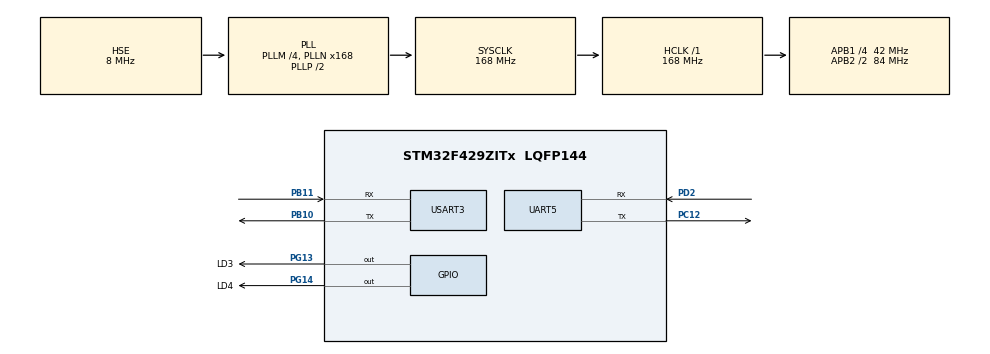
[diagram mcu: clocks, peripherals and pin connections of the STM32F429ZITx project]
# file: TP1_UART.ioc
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Mcu.Family=STM32F4
Mcu.Name=STM32F429ZITx
Mcu.Package=LQFP144
NVIC.PriorityGroup=NVIC_PRIORITYGROUP_4
NVIC.UART5_IRQn=true\:0\:0\:false\:false\:true\:true\:true
NVIC.USART3_IRQn=true\:0\:0\:false\:false\:true\:true\:true
PB10.Mode=Asynchronous
PB10.Signal=USART3_TX
PB11.Mode=Asynchronous
PB11.Signal=USART3_RX
PC12.Mode=Asynchronous
PC12.Signal=UART5_TX
PD2.Mode=Asynchronous
PD2.Signal=UART5_RX
PG13.GPIO_Label=LD3
PG13.Signal=GPIO_Output
PG14.GPIO_Label=LD4
PG14.Signal=GPIO_Output
PH0/OSC_IN.Mode=HSE-External-Oscillator
PH0/OSC_IN.Signal=RCC_OSC_IN
PH1/OSC_OUT.Mode=HSE-External-Oscillator
PH1/OSC_OUT.Signal=RCC_OSC_OUT
ProjectManager.HeapSize=0x200
ProjectManager.StackSize=0x400
ProjectManager.TargetToolchain=STM32CubeIDE
RCC.48MHZClocksFreq_Value=112000000
RCC.AHBFreq_Value=168000000
RCC.APB1CLKDivider=RCC_HCLK_DIV4
RCC.APB1Freq_Value=42000000
RCC.APB1TimFreq_Value=84000000
RCC.APB2CLKDivider=RCC_HCLK_DIV2
RCC.APB2Freq_Value=84000000
RCC.APB2TimFreq_Value=168000000
RCC.CortexFreq_Value=168000000
RCC.HCLKFreq_Value=168000000
RCC.HSE_VALUE=8000000
RCC.HSI_VALUE=16000000
RCC.LSE_VALUE=32768
RCC.PLLM=4
RCC.PLLN=168
RCC.PLLQ=3
RCC.PLLSAIN=50
RCC.PLLSourceVirtual=RCC_PLLSOURCE_HSE
RCC.SYSCLKFreq_VALUE=168000000
RCC.SYSCLKSource=RCC_SYSCLKSOURCE_PLLCLK
RCC.VCOOutputFreq_Value=336000000
UART5.VirtualMode=Asynchronous
UART5.WordLength=WORDLENGTH_8B
USART3.VirtualMode=VM_ASYNC
USART3.WordLength=WORDLENGTH_8B
board=STM32F429I-DISC1

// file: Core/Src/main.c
/* USER CODE BEGIN Header */
/**
  ******************************************************************************
  * @file           : main.c
  * @brief          : Main program body
  ******************************************************************************
  * @attention
  *
  * <h2><center>&copy; Copyright (c) 2020 STMicroelectronics.
  * All rights reserved.</center></h2>
  *
  * This software component is licensed by ST under Ultimate Liberty license
  * SLA0044, the "License"; You may not use this file except in compliance with
  * the License. You may obtain a copy of the License at:
  *                             www.st.com/SLA0044
  *
  ******************************************************************************
  */
/* USER CODE END Header */
#include "main.h"

UART_HandleTypeDef huart5;
UART_HandleTypeDef huart3;
uint8_t TableRxUART3[SIZE] = {0x31, 0x32, 0x33, 0x34, 0x35};
uint8_t TableRxUART5[SIZE] = {0x51, 0x52, 0x53, 0x54, 0x55};

void SystemClock_Config(void);
static void MX_GPIO_Init(void);
static void MX_UART5_Init(void);
static void MX_USART3_UART_Init(void);

int main(void)
{

  /* MCU Configuration--------------------------------------------------------*/

  /* Reset of all peripherals, Initializes the Flash interface and the Systick. */
  HAL_Init();

  /* Configure the system clock */
  SystemClock_Config();

  /* Initialize all configured peripherals */
  MX_GPIO_Init();
  MX_UART5_Init();
  MX_USART3_UART_Init();

  /* USER CODE BEGIN 2 */

  __HAL_UART_ENABLE_IT(&huart3, UART_IT_RXNE);
  __HAL_UART_ENABLE_IT(&huart5, UART_IT_RXNE);

  /* USER CODE END 2 */

  /* Infinite loop */
  while (1)
  {
	// Initialisation des tableaux de reception
	for(int i=0; i<SIZE; i++)
	{
		TableTxUART3[i]='\0';
		TableTxUART5[i]='\0';
	}
	HAL_GPIO_WritePin(LD3_GPIO_Port, LD3_Pin, 1);
	HAL_UART_Transmit(&huart3, TableRxUART3, SIZE, 100);
	HAL_UART_Transmit(&huart5, TableRxUART5, SIZE, 100);
	HAL_GPIO_WritePin(LD3_GPIO_Port, LD3_Pin, 0);
  }
}

void SystemClock_Config(void)
{
  RCC_OscInitTypeDef RCC_OscInitStruct = {0};
  RCC_ClkInitTypeDef RCC_ClkInitStruct = {0};

  /** Configure the main internal regulator output voltage
  */
  __HAL_RCC_PWR_CLK_ENABLE();
  __HAL_PWR_VOLTAGESCALING_CONFIG(PWR_REGULATOR_VOLTAGE_SCALE1);
  /** Initializes the RCC Oscillators according to the specified parameters
  * in the RCC_OscInitTypeDef structure.
  */
  RCC_OscInitStruct.OscillatorType = RCC_OSCILLATORTYPE_HSE;
  RCC_OscInitStruct.HSEState = RCC_HSE_ON;
  RCC_OscInitStruct.PLL.PLLState = RCC_PLL_ON;
  RCC_OscInitStruct.PLL.PLLSource = RCC_PLLSOURCE_HSE;
  RCC_OscInitStruct.PLL.PLLM = 4;
  RCC_OscInitStruct.PLL.PLLN = 168;
  RCC_OscInitStruct.PLL.PLLP = RCC_PLLP_DIV2;
  RCC_OscInitStruct.PLL.PLLQ = 3;
  if (HAL_RCC_OscConfig(&RCC_OscInitStruct) != HAL_OK)
  {
    Error_Handler();
  }
  /** Initializes the CPU, AHB and APB buses clocks
  */
  RCC_ClkInitStruct.ClockType = RCC_CLOCKTYPE_HCLK|RCC_CLOCKTYPE_SYSCLK
                              |RCC_CLOCKTYPE_PCLK1|RCC_CLOCKTYPE_PCLK2;
  RCC_ClkInitStruct.SYSCLKSource = RCC_SYSCLKSOURCE_PLLCLK;
  RCC_ClkInitStruct.AHBCLKDivider = RCC_SYSCLK_DIV1;
  RCC_ClkInitStruct.APB1CLKDivider = RCC_HCLK_DIV4;
  RCC_ClkInitStruct.APB2CLKDivider = RCC_HCLK_DIV2;

  if (HAL_RCC_ClockConfig(&RCC_ClkInitStruct, FLASH_LATENCY_5) != HAL_OK)
  {
    Error_Handler();
  }
}

static void MX_UART5_Init(void)
{

  huart5.Instance = UART5;
  huart5.Init.BaudRate = 115200;
  huart5.Init.WordLength = UART_WORDLENGTH_8B;
  huart5.Init.StopBits = UART_STOPBITS_1;
  huart5.Init.Parity = UART_PARITY_NONE;
  huart5.Init.Mode = UART_MODE_TX_RX;
  huart5.Init.HwFlowCtl = UART_HWCONTROL_NONE;
  huart5.Init.OverSampling = UART_OVERSAMPLING_16;
  if (HAL_UART_Init(&huart5) != HAL_OK)
  {
    Error_Handler();
  }

}

static void MX_USART3_UART_Init(void)
{

  huart3.Instance = USART3;
  huart3.Init.BaudRate = 115200;
  huart3.Init.WordLength = UART_WORDLENGTH_8B;
  huart3.Init.StopBits = UART_STOPBITS_1;
  huart3.Init.Parity = UART_PARITY_NONE;
  huart3.Init.Mode = UART_MODE_TX_RX;
  huart3.Init.HwFlowCtl = UART_HWCONTROL_NONE;
  huart3.Init.OverSampling = UART_OVERSAMPLING_16;
  if (HAL_UART_Init(&huart3) != HAL_OK)
  {
    Error_Handler();
  }

}

static void MX_GPIO_Init(void)
{
  GPIO_InitTypeDef GPIO_InitStruct = {0};

  /* GPIO Ports Clock Enable */
  __HAL_RCC_GPIOH_CLK_ENABLE();
  __HAL_RCC_GPIOB_CLK_ENABLE();
  __HAL_RCC_GPIOC_CLK_ENABLE();
  __HAL_RCC_GPIOD_CLK_ENABLE();
  __HAL_RCC_GPIOG_CLK_ENABLE();

  /*Configure GPIO pin Output Level */
  HAL_GPIO_WritePin(GPIOG, LD3_Pin|LD4_Pin, GPIO_PIN_RESET);

  /*Configure GPIO pins : LD3_Pin LD4_Pin */
  GPIO_InitStruct.Pin = LD3_Pin|LD4_Pin;
  GPIO_InitStruct.Mode = GPIO_MODE_OUTPUT_PP;
  GPIO_InitStruct.Pull = GPIO_NOPULL;
  GPIO_InitStruct.Speed = GPIO_SPEED_FREQ_LOW;
  HAL_GPIO_Init(GPIOG, &GPIO_InitStruct);

}

void Error_Handler(void)
{
}

/************************ (C) COPYRIGHT STMicroelectronics *****END OF FILE****/
